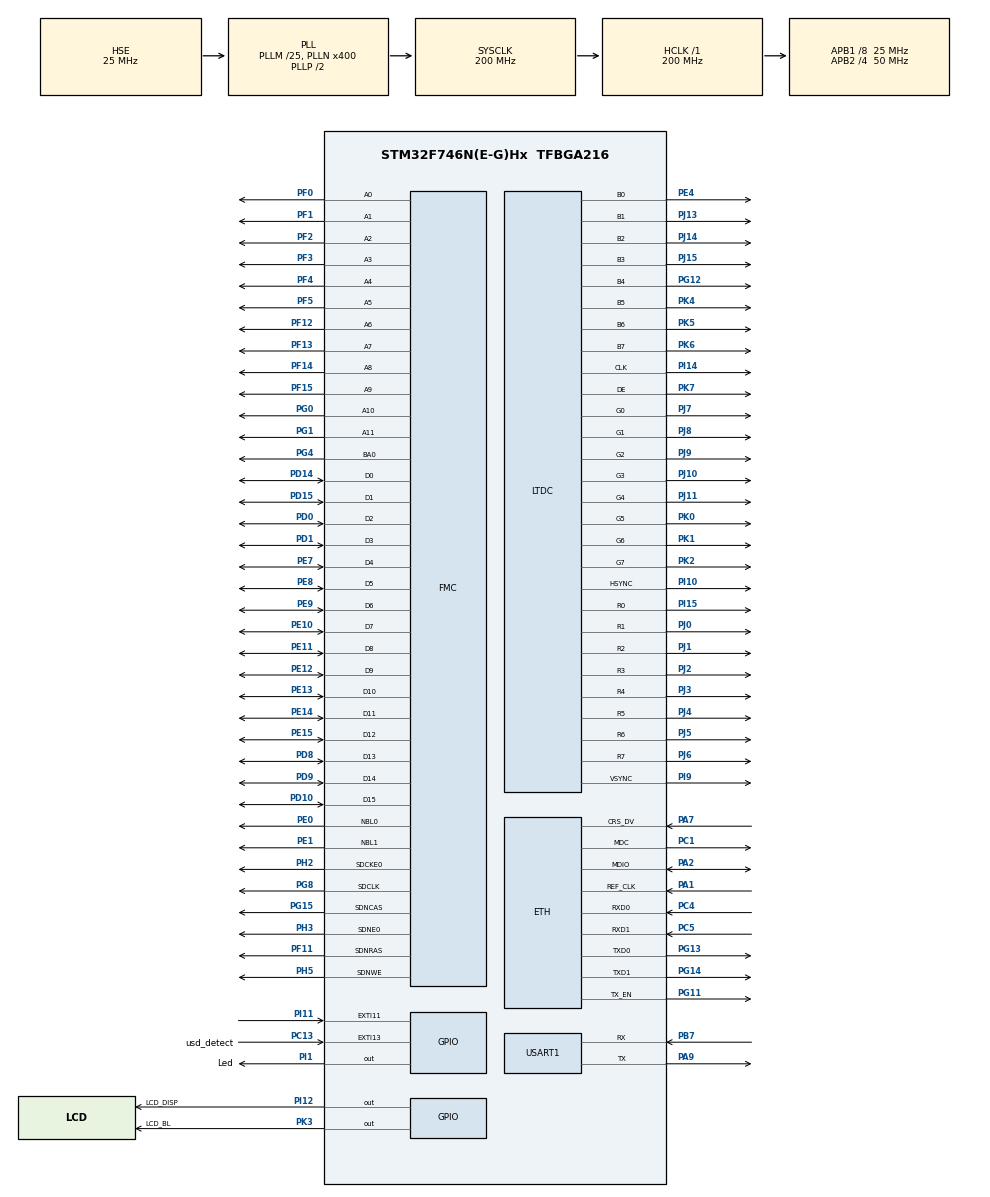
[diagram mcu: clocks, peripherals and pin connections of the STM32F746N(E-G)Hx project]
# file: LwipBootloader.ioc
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DMA2D.ColorMode=DMA2D_OUTPUT_ARGB1555
DMA2D.InputAlphaForeground=0
DMA2D.InputColorModeForeground=DMA2D_INPUT_A8
DMA2D.InputOffsetForeground=121
DMA2D.Mode=DMA2D_M2M_PFC
DMA2D.OutputOffset=473
ETH.MediaInterface=ETH_MEDIA_INTERFACE_RMII
ETH.PhyAddress=0
LTDC.ActiveH=272
LTDC.ActiveW=480
LTDC.HBP=43
LTDC.HFP=8
LTDC.HSync=1
LTDC.VBP=12
LTDC.VFP=4
LTDC.VSync=1
LWIP.GATEWAY_ADDRESS=192.168.002.001
LWIP.IP_ADDRESS=192.168.002.002
LWIP.LWIP_DHCP=0
LWIP.LWIP_UDP=1
LWIP.NETMASK_ADDRESS=255.255.255.000
LWIP.Version=v1.5.0_RC0_20160211_Cube
Mcu.Family=STM32F7
Mcu.Name=STM32F746N(E-G)Hx
Mcu.Package=TFBGA216
NVIC.EXTI15_10_IRQn=true\:0\:0\:false\:false\:true
NVIC.PriorityGroup=NVIC_PRIORITYGROUP_4
NVIC.TIM2_IRQn=true\:0\:0\:false\:false\:true
PA1.Mode=RMII
PA1.Signal=ETH_REF_CLK
PA2.Mode=RMII
PA2.Signal=ETH_MDIO
PA7.Mode=RMII
PA7.Signal=ETH_CRS_DV
PA9.Mode=Asynchronous
PA9.Signal=USART1_TX
PB7.Mode=Asynchronous
PB7.Signal=USART1_RX
PC1.Mode=RMII
PC1.Signal=ETH_MDC
PC13.GPIO_Label=usd_detect
PC13.GPIO_ModeDefaultEXTI=GPIO_MODE_IT_FALLING
PC13.Signal=GPXTI13
PC14/OSC32_IN.Mode=LSE-External-Oscillator
PC14/OSC32_IN.Signal=RCC_OSC32_IN
PC15/OSC32_OUT.Mode=LSE-External-Oscillator
PC15/OSC32_OUT.Signal=RCC_OSC32_OUT
PC4.Mode=RMII
PC4.Signal=ETH_RXD0
PC5.Mode=RMII
PC5.Signal=ETH_RXD1
PD0.Signal=FMC_D2_DA2
PD1.Signal=FMC_D3_DA3
PD10.Signal=FMC_D15_DA15
PD14.Signal=FMC_D0_DA0
PD15.Signal=FMC_D1_DA1
PD8.Signal=FMC_D13_DA13
PD9.Signal=FMC_D14_DA14
PE0.Signal=FMC_NBL0
PE1.Signal=FMC_NBL1
PE10.Signal=FMC_D7_DA7
PE11.Signal=FMC_D8_DA8
PE12.Signal=FMC_D9_DA9
PE13.Signal=FMC_D10_DA10
PE14.Signal=FMC_D11_DA11
PE15.Signal=FMC_D12_DA12
PE4.Mode=RGB888
PE4.Signal=LTDC_B0
PE7.Signal=FMC_D4_DA4
PE8.Signal=FMC_D5_DA5
PE9.Signal=FMC_D6_DA6
PF0.Signal=FMC_A0
PF1.Signal=FMC_A1
PF11.Signal=FMC_SDNRAS
PF12.Signal=FMC_A6
PF13.Signal=FMC_A7
PF14.Signal=FMC_A8
PF15.Signal=FMC_A9
PF2.Signal=FMC_A2
PF3.Signal=FMC_A3
PF4.Signal=FMC_A4
PF5.Signal=FMC_A5
PG0.Signal=FMC_A10
PG1.Signal=FMC_A11
PG11.Mode=RMII
PG11.Signal=ETH_TX_EN
PG12.Mode=RGB888
PG12.Signal=LTDC_B4
PG13.Mode=RMII
PG13.Signal=ETH_TXD0
PG14.Mode=RMII
PG14.Signal=ETH_TXD1
PG15.Signal=FMC_SDNCAS
PG4.Signal=FMC_A14_BA0
PG8.Signal=FMC_SDCLK
PH0/OSC_IN.Mode=HSE-External-Oscillator
PH0/OSC_IN.Signal=RCC_OSC_IN
PH1/OSC_OUT.Mode=HSE-External-Oscillator
PH1/OSC_OUT.Signal=RCC_OSC_OUT
PH2.Mode=SdramChipSelect1_1
PH2.Signal=FMC_SDCKE0
PH3.Mode=SdramChipSelect1_1
PH3.Signal=FMC_SDNE0
PH5.Signal=FMC_SDNWE
PH7.Signal=I2C3_SCL
PH8.Signal=I2C3_SDA
PI1.GPIO_Label=Led
PI1.Signal=GPIO_Output
PI10.Mode=RGB888
PI10.Signal=LTDC_HSYNC
PI11.Signal=GPXTI11
PI12.GPIO_Label=LCD_DISP
PI12.Signal=GPIO_Output
PI14.Mode=RGB888
PI14.Signal=LTDC_CLK
PI15.Mode=RGB888
PI15.Signal=LTDC_R0
PI9.Mode=RGB888
PI9.Signal=LTDC_VSYNC
PJ0.Mode=RGB888
PJ0.Signal=LTDC_R1
PJ1.Mode=RGB888
PJ1.Signal=LTDC_R2
PJ10.Mode=RGB888
PJ10.Signal=LTDC_G3
PJ11.Mode=RGB888
PJ11.Signal=LTDC_G4
PJ13.Mode=RGB888
PJ13.Signal=LTDC_B1
PJ14.Mode=RGB888
PJ14.Signal=LTDC_B2
PJ15.Mode=RGB888
PJ15.Signal=LTDC_B3
PJ2.Mode=RGB888
PJ2.Signal=LTDC_R3
PJ3.Mode=RGB888
PJ3.Signal=LTDC_R4
PJ4.Mode=RGB888
PJ4.Signal=LTDC_R5
PJ5.Mode=RGB888
PJ5.Signal=LTDC_R6
PJ6.Mode=RGB888
PJ6.Signal=LTDC_R7
PJ7.Mode=RGB888
PJ7.Signal=LTDC_G0
PJ8.Mode=RGB888
PJ8.Signal=LTDC_G1
PJ9.Mode=RGB888
PJ9.Signal=LTDC_G2
PK0.Mode=RGB888
PK0.Signal=LTDC_G5
PK1.Mode=RGB888
PK1.Signal=LTDC_G6
PK2.Mode=RGB888
PK2.Signal=LTDC_G7
PK3.GPIO_Label=LCD_BL
PK3.Signal=GPIO_Output
PK4.Mode=RGB888
PK4.Signal=LTDC_B5
PK5.Mode=RGB888
PK5.Signal=LTDC_B6
PK6.Mode=RGB888
PK6.Signal=LTDC_B7
PK7.Mode=RGB888
PK7.Signal=LTDC_DE
ProjectManager.HeapSize=0x200
ProjectManager.StackSize=0x400
ProjectManager.TargetToolchain=SW4STM32
RCC.AHBFreq_Value=200000000
RCC.APB1CLKDivider=RCC_HCLK_DIV8
RCC.APB1Freq_Value=25000000
RCC.APB1TimFreq_Value=50000000
RCC.APB2CLKDivider=RCC_HCLK_DIV4
RCC.APB2Freq_Value=50000000
RCC.APB2TimFreq_Value=100000000
RCC.CortexFreq_Value=200000000
RCC.HCLKFreq_Value=200000000
RCC.HSE_VALUE=25000000
RCC.HSI_VALUE=16000000
RCC.PLLM=25
RCC.PLLN=400
RCC.PLLQ=8
RCC.PLLSAIR=5
RCC.PLLSAIRDiv=RCC_PLLSAIDIVR_4
RCC.PLLSourceVirtual=RCC_PLLSOURCE_HSE
RCC.SDMMCClockSelection=RCC_SDMMC1CLKSOURCE_CLK48
RCC.SYSCLKFreq_VALUE=200000000
RCC.SYSCLKSource=RCC_SYSCLKSOURCE_PLLCLK
RCC.USBFreq_Value=50000000
RCC.VCOOutputFreq_Value=400000000
SH.FMC_A0.0=FMC_A0,12b-sda1
SH.FMC_A1.0=FMC_A1,12b-sda1
SH.FMC_A10.0=FMC_A10,12b-sda1
SH.FMC_A11.0=FMC_A11,12b-sda1
SH.FMC_A14_BA0.0=FMC_BA0,TwoSdramBanks1
SH.FMC_A2.0=FMC_A2,12b-sda1
SH.FMC_A3.0=FMC_A3,12b-sda1
SH.FMC_A4.0=FMC_A4,12b-sda1
SH.FMC_A5.0=FMC_A5,12b-sda1
SH.FMC_A6.0=FMC_A6,12b-sda1
SH.FMC_A7.0=FMC_A7,12b-sda1
SH.FMC_A8.0=FMC_A8,12b-sda1
SH.FMC_A9.0=FMC_A9,12b-sda1
SH.FMC_D0_DA0.0=FMC_D0,sd-16b-d1
SH.FMC_D10_DA10.0=FMC_D10,sd-16b-d1
SH.FMC_D11_DA11.0=FMC_D11,sd-16b-d1
SH.FMC_D12_DA12.0=FMC_D12,sd-16b-d1
SH.FMC_D13_DA13.0=FMC_D13,sd-16b-d1
SH.FMC_D14_DA14.0=FMC_D14,sd-16b-d1
SH.FMC_D15_DA15.0=FMC_D15,sd-16b-d1
SH.FMC_D1_DA1.0=FMC_D1,sd-16b-d1
SH.FMC_D2_DA2.0=FMC_D2,sd-16b-d1
SH.FMC_D3_DA3.0=FMC_D3,sd-16b-d1
SH.FMC_D4_DA4.0=FMC_D4,sd-16b-d1
SH.FMC_D5_DA5.0=FMC_D5,sd-16b-d1
SH.FMC_D6_DA6.0=FMC_D6,sd-16b-d1
SH.FMC_D7_DA7.0=FMC_D7,sd-16b-d1
SH.FMC_D8_DA8.0=FMC_D8,sd-16b-d1
SH.FMC_D9_DA9.0=FMC_D9,sd-16b-d1
SH.FMC_NBL0.0=FMC_NBL0,Sd2ByteEnable1
SH.FMC_NBL1.0=FMC_NBL1,Sd2ByteEnable1
SH.FMC_SDCLK.0=FMC_SDCLK,12b-sda1
SH.FMC_SDNCAS.0=FMC_SDNCAS,12b-sda1
SH.FMC_SDNRAS.0=FMC_SDNRAS,12b-sda1
SH.FMC_SDNWE.0=FMC_SDNWE,12b-sda1
TIM2.Period=500
TIM2.Prescaler=50000
USART1.WordLength=UART_WORDLENGTH_8B
VP_DMA2D_VS_DMA2D.Mode=DMA2D_Activate
VP_LWIP_VS_Enabled.Mode=Enabled
VP_TIM2_VS_ClockSourceINT.Mode=Internal
board=STM32F746G-DISCO

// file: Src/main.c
/**
  ******************************************************************************
  * File Name          : main.c
  * Description        : Main program body
  ******************************************************************************
  *
  * Copyright (c) 2016 STMicroelectronics International N.V.
  * All rights reserved.
  *
  * Redistribution and use in source and binary forms, with or without
  * modification, are permitted, provided that the following conditions are met:
  *
  * 1. Redistribution of source code must retain the above copyright notice,
  *    this list of conditions and the following disclaimer.
  * 2. Redistributions in binary form must reproduce the above copyright notice,
  *    this list of conditions and the following disclaimer in the documentation
  *    and/or other materials provided with the distribution.
  * 3. Neither the name of STMicroelectronics nor the names of other
  *    contributors to this software may be used to endorse or promote products
  *    derived from this software without specific written permission.
  * 4. This software, including modifications and/or derivative works of this
  *    software, must execute solely and exclusively on microcontroller or
  *    microprocessor devices manufactured by or for STMicroelectronics.
  * 5. Redistribution and use of this software other than as permitted under
  *    this license is void and will automatically terminate your rights under
  *    this license.
  *
  * THIS SOFTWARE IS PROVIDED BY STMICROELECTRONICS AND CONTRIBUTORS "AS IS"
  * AND ANY EXPRESS, IMPLIED OR STATUTORY WARRANTIES, INCLUDING, BUT NOT
  * LIMITED TO, THE IMPLIED WARRANTIES OF MERCHANTABILITY, FITNESS FOR A
  * PARTICULAR PURPOSE AND NON-INFRINGEMENT OF THIRD PARTY INTELLECTUAL PROPERTY
  * RIGHTS ARE DISCLAIMED TO THE FULLEST EXTENT PERMITTED BY LAW. IN NO EVENT
  * SHALL STMICROELECTRONICS OR CONTRIBUTORS BE LIABLE FOR ANY DIRECT, INDIRECT,
  * INCIDENTAL, SPECIAL, EXEMPLARY, OR CONSEQUENTIAL DAMAGES (INCLUDING, BUT NOT
  * LIMITED TO, PROCUREMENT OF SUBSTITUTE GOODS OR SERVICES; LOSS OF USE, DATA,
  * OR PROFITS; OR BUSINESS INTERRUPTION) HOWEVER CAUSED AND ON ANY THEORY OF
  * LIABILITY, WHETHER IN CONTRACT, STRICT LIABILITY, OR TORT (INCLUDING
  * NEGLIGENCE OR OTHERWISE) ARISING IN ANY WAY OUT OF THE USE OF THIS SOFTWARE,
  * EVEN IF ADVISED OF THE POSSIBILITY OF SUCH DAMAGE.
  *
  ******************************************************************************
  */
#include "main.h"
#include "stm32f7xx_hal.h"
#include "lwip.h"

/* USER CODE BEGIN Includes */

#include "tcp.h"
#include "udp.h"
#include "oli/oli_tcp.h"
#include "oli/oli_discover.h"
#include "oli/oli_text.h"
#include "oli/oli_bootloader.h"

#include "sdram/stm32746g_discovery_sdram.h"

/* Begin defines */

#define mainLCD_FB_START_ADDRESS       ((uint32_t)0xC0000000)

/* End defines */

/* USER CODE END Includes */

DMA2D_HandleTypeDef hdma2d;
LTDC_HandleTypeDef hltdc;
TIM_HandleTypeDef htim2;
UART_HandleTypeDef huart1;
SDRAM_HandleTypeDef hsdram1;

/* USER CODE BEGIN PV */
/* Private variables ---------------------------------------------------------*/

/**
 * Bij deze variabele word er een sectie aangemaakt in het geheugen.
 * Het doel is om deze variabele in het begin van de ram te plaatsen(0x20000000).
 * Dit moet omdat deze gebruikt zal worden een een dynamische vectortabel in te laden voor de user applicatie.
 * Deze sectie wordt gedefinierd in het linker script
 */
__attribute__((section(".user_vector"))) uint32_t userVectorTable[80];

uint8_t ucUserAppIsRunning = 0;
uint8_t * pucUserAppName = otcpAPPLICATION_NAME_ADDRESS;

/* USER CODE END PV */

void SystemClock_Config(void);
void Error_Handler(void);
static void MX_GPIO_Init(void);
static void MX_LTDC_Init(void);
static void MX_DMA2D_Init(void);
static void MX_USART1_UART_Init(void);
static void MX_TIM2_Init(void);
static void MX_FMC_Init(void);

/* USER CODE BEGIN PFP */
/* Private function prototypes -----------------------------------------------*/

err_t xMainClientConnected( void * pvArg, struct tcp_pcb * pxNewpcb, err_t xErr );

/*-----------------------------------------------------------*/

/* USER CODE END PFP */

int main(void)
{

  /* USER CODE BEGIN 1 */

	MX_GPIO_Init();
	MX_TIM2_Init();
	// We kijken of de knop ingedrukt is
	if( !HAL_GPIO_ReadPin( GPIOI, GPIO_PIN_11 ) && *pucUserAppName != 15 )
	{
		// Als de knop niet ingedrukt is springen we naar het programma in flash
		vObootloaderJumpToApplication( otcpAPPLICATION_ADDRESS );
	}

	if( *pucUserAppName == 15 )
	{
		// We zijn herstart zoals gevraagd over udp, nu terug naar normale werking
		// We moeten dus terug 14 voor de user-app naam schrijven
		HAL_FLASH_Unlock();
		HAL_FLASH_Program( FLASH_TYPEPROGRAM_BYTE, otcpAPPLICATION_NAME_ADDRESS, 14 );
		HAL_FLASH_Lock();
	}

  /* USER CODE END 1 */

  /* MCU Configuration----------------------------------------------------------*/

  /* Reset of all peripherals, Initializes the Flash interface and the Systick. */
  HAL_Init();

  /* Configure the system clock */
  SystemClock_Config();

  /* Initialize all configured peripherals */
  MX_GPIO_Init();
  MX_LTDC_Init();
  MX_DMA2D_Init();
  MX_USART1_UART_Init();
  MX_LWIP_Init();
  MX_TIM2_Init();
  MX_FMC_Init();

  /* USER CODE BEGIN 2 */

  struct ip4_addr xServerIp;
  struct tcp_pcb * pxTcpConnectie;

  IP4_ADDR( &xServerIp, 192, 168, 2, 2 );

  // We maken een nieuwe tcp server en laten deze luisteren op poort 5555
  pxTcpConnectie = tcp_new();
  tcp_bind( pxTcpConnectie, &xServerIp, otcpBOOTLOADER_SERVER_PORT );
  pxTcpConnectie = tcp_listen_with_backlog( pxTcpConnectie, 1 );
  if( pxTcpConnectie != NULL )
  {
	  tcp_accept( pxTcpConnectie, xMainClientConnected );
  }

  // We initialiseren udp zodat we op het netwerk gevonden kunnen worden via een broadcast
  vOdiscoverInitUdpDiscover();

  // We tonen een welcomeMessage op het lcd
  BSP_SDRAM_Init();
  vOtextInitLcd( &hltdc, &hdma2d, mainLCD_FB_START_ADDRESS );
  vOtextWriteString( 184, 50, otcpWELCOME );

  /* USER CODE END 2 */

  /* Infinite loop */
  while ( 1 )
  {

  /* USER CODE BEGIN 3 */

	  MX_LWIP_Process();

  }
  /* USER CODE END 3 */

}

/** System Clock Configuration
*/
void SystemClock_Config(void)
{

  RCC_OscInitTypeDef RCC_OscInitStruct;
  RCC_ClkInitTypeDef RCC_ClkInitStruct;
  RCC_PeriphCLKInitTypeDef PeriphClkInitStruct;

    /**Configure the main internal regulator output voltage
    */
  __HAL_RCC_PWR_CLK_ENABLE();

  __HAL_PWR_VOLTAGESCALING_CONFIG(PWR_REGULATOR_VOLTAGE_SCALE1);

    /**Initializes the CPU, AHB and APB busses clocks
    */
  RCC_OscInitStruct.OscillatorType = RCC_OSCILLATORTYPE_HSE;
  RCC_OscInitStruct.HSEState = RCC_HSE_ON;
  RCC_OscInitStruct.PLL.PLLState = RCC_PLL_ON;
  RCC_OscInitStruct.PLL.PLLSource = RCC_PLLSOURCE_HSE;
  RCC_OscInitStruct.PLL.PLLM = 25;
  RCC_OscInitStruct.PLL.PLLN = 400;
  RCC_OscInitStruct.PLL.PLLP = RCC_PLLP_DIV2;
  RCC_OscInitStruct.PLL.PLLQ = 8;
  if (HAL_RCC_OscConfig(&RCC_OscInitStruct) != HAL_OK)
  {
    Error_Handler();
  }

    /**Activate the Over-Drive mode
    */
  if (HAL_PWREx_EnableOverDrive() != HAL_OK)
  {
    Error_Handler();
  }

    /**Initializes the CPU, AHB and APB busses clocks
    */
  RCC_ClkInitStruct.ClockType = RCC_CLOCKTYPE_HCLK|RCC_CLOCKTYPE_SYSCLK
                              |RCC_CLOCKTYPE_PCLK1|RCC_CLOCKTYPE_PCLK2;
  RCC_ClkInitStruct.SYSCLKSource = RCC_SYSCLKSOURCE_PLLCLK;
  RCC_ClkInitStruct.AHBCLKDivider = RCC_SYSCLK_DIV1;
  RCC_ClkInitStruct.APB1CLKDivider = RCC_HCLK_DIV8;
  RCC_ClkInitStruct.APB2CLKDivider = RCC_HCLK_DIV4;

  if (HAL_RCC_ClockConfig(&RCC_ClkInitStruct, FLASH_LATENCY_6) != HAL_OK)
  {
    Error_Handler();
  }

  PeriphClkInitStruct.PeriphClockSelection = RCC_PERIPHCLK_LTDC|RCC_PERIPHCLK_USART1;
  PeriphClkInitStruct.PLLSAI.PLLSAIN = 192;
  PeriphClkInitStruct.PLLSAI.PLLSAIR = 5;
  PeriphClkInitStruct.PLLSAI.PLLSAIQ = 2;
  PeriphClkInitStruct.PLLSAI.PLLSAIP = RCC_PLLSAIP_DIV2;
  PeriphClkInitStruct.PLLSAIDivQ = 1;
  PeriphClkInitStruct.PLLSAIDivR = RCC_PLLSAIDIVR_4;
  PeriphClkInitStruct.Usart1ClockSelection = RCC_USART1CLKSOURCE_PCLK2;
  if (HAL_RCCEx_PeriphCLKConfig(&PeriphClkInitStruct) != HAL_OK)
  {
    Error_Handler();
  }

    /**Configure the Systick interrupt time
    */
  HAL_SYSTICK_Config(HAL_RCC_GetHCLKFreq()/1000);

    /**Configure the Systick
    */
  HAL_SYSTICK_CLKSourceConfig(SYSTICK_CLKSOURCE_HCLK);

  /* SysTick_IRQn interrupt configuration */
  HAL_NVIC_SetPriority(SysTick_IRQn, 0, 0);
}

/* DMA2D init function */
static void MX_DMA2D_Init(void)
{

  hdma2d.Instance = DMA2D;
  hdma2d.Init.Mode = DMA2D_M2M_PFC;
  hdma2d.Init.ColorMode = DMA2D_OUTPUT_ARGB1555;
  hdma2d.Init.OutputOffset = 473;
  hdma2d.LayerCfg[1].InputOffset = 121;
  hdma2d.LayerCfg[1].InputColorMode = DMA2D_INPUT_A8;
  hdma2d.LayerCfg[1].AlphaMode = DMA2D_NO_MODIF_ALPHA;
  hdma2d.LayerCfg[1].InputAlpha = 0;
  if (HAL_DMA2D_Init(&hdma2d) != HAL_OK)
  {
    Error_Handler();
  }

  if (HAL_DMA2D_ConfigLayer(&hdma2d, 1) != HAL_OK)
  {
    Error_Handler();
  }

}

/* LTDC init function */
static void MX_LTDC_Init(void)
{

  LTDC_LayerCfgTypeDef pLayerCfg;
  LTDC_LayerCfgTypeDef pLayerCfg1;

  hltdc.Instance = LTDC;
  hltdc.Init.HSPolarity = LTDC_HSPOLARITY_AL;
  hltdc.Init.VSPolarity = LTDC_VSPOLARITY_AL;
  hltdc.Init.DEPolarity = LTDC_DEPOLARITY_AL;
  hltdc.Init.PCPolarity = LTDC_PCPOLARITY_IPC;
  hltdc.Init.HorizontalSync = 0;
  hltdc.Init.VerticalSync = 0;
  hltdc.Init.AccumulatedHBP = 43;
  hltdc.Init.AccumulatedVBP = 12;
  hltdc.Init.AccumulatedActiveW = 523;
  hltdc.Init.AccumulatedActiveH = 284;
  hltdc.Init.TotalWidth = 531;
  hltdc.Init.TotalHeigh = 288;
  hltdc.Init.Backcolor.Blue = 0;
  hltdc.Init.Backcolor.Green = 0;
  hltdc.Init.Backcolor.Red = 0;
  if (HAL_LTDC_Init(&hltdc) != HAL_OK)
  {
    Error_Handler();
  }

  pLayerCfg.WindowX0 = 0;
  pLayerCfg.WindowX1 = 0;
  pLayerCfg.WindowY0 = 0;
  pLayerCfg.WindowY1 = 0;
  pLayerCfg.PixelFormat = LTDC_PIXEL_FORMAT_ARGB8888;
  pLayerCfg.Alpha = 0;
  pLayerCfg.Alpha0 = 0;
  pLayerCfg.BlendingFactor1 = LTDC_BLENDING_FACTOR1_CA;
  pLayerCfg.BlendingFactor2 = LTDC_BLENDING_FACTOR2_CA;
  pLayerCfg.FBStartAdress = 0;
  pLayerCfg.ImageWidth = 0;
  pLayerCfg.ImageHeight = 0;
  pLayerCfg.Backcolor.Blue = 0;
  pLayerCfg.Backcolor.Green = 0;
  pLayerCfg.Backcolor.Red = 0;
  if (HAL_LTDC_ConfigLayer(&hltdc, &pLayerCfg, 0) != HAL_OK)
  {
    Error_Handler();
  }

  pLayerCfg1.WindowX0 = 0;
  pLayerCfg1.WindowX1 = 0;
  pLayerCfg1.WindowY0 = 0;
  pLayerCfg1.WindowY1 = 0;
  pLayerCfg1.PixelFormat = LTDC_PIXEL_FORMAT_ARGB8888;
  pLayerCfg1.Alpha = 0;
  pLayerCfg1.Alpha0 = 0;
  pLayerCfg1.BlendingFactor1 = LTDC_BLENDING_FACTOR1_CA;
  pLayerCfg1.BlendingFactor2 = LTDC_BLENDING_FACTOR2_CA;
  pLayerCfg1.FBStartAdress = 0;
  pLayerCfg1.ImageWidth = 0;
  pLayerCfg1.ImageHeight = 0;
  pLayerCfg1.Backcolor.Blue = 0;
  pLayerCfg1.Backcolor.Green = 0;
  pLayerCfg1.Backcolor.Red = 0;
  if (HAL_LTDC_ConfigLayer(&hltdc, &pLayerCfg1, 1) != HAL_OK)
  {
    Error_Handler();
  }

}

/* TIM2 init function */
static void MX_TIM2_Init(void)
{

  TIM_ClockConfigTypeDef sClockSourceConfig;
  TIM_MasterConfigTypeDef sMasterConfig;

  htim2.Instance = TIM2;
  htim2.Init.Prescaler = 50000;
  htim2.Init.CounterMode = TIM_COUNTERMODE_UP;
  htim2.Init.Period = 500;
  htim2.Init.ClockDivision = TIM_CLOCKDIVISION_DIV1;
  if (HAL_TIM_Base_Init(&htim2) != HAL_OK)
  {
    Error_Handler();
  }

  sClockSourceConfig.ClockSource = TIM_CLOCKSOURCE_INTERNAL;
  if (HAL_TIM_ConfigClockSource(&htim2, &sClockSourceConfig) != HAL_OK)
  {
    Error_Handler();
  }

  sMasterConfig.MasterOutputTrigger = TIM_TRGO_RESET;
  sMasterConfig.MasterSlaveMode = TIM_MASTERSLAVEMODE_DISABLE;
  if (HAL_TIMEx_MasterConfigSynchronization(&htim2, &sMasterConfig) != HAL_OK)
  {
    Error_Handler();
  }

}

/* USART1 init function */
static void MX_USART1_UART_Init(void)
{

  huart1.Instance = USART1;
  huart1.Init.BaudRate = 115200;
  huart1.Init.WordLength = UART_WORDLENGTH_8B;
  huart1.Init.StopBits = UART_STOPBITS_1;
  huart1.Init.Parity = UART_PARITY_NONE;
  huart1.Init.Mode = UART_MODE_TX_RX;
  huart1.Init.HwFlowCtl = UART_HWCONTROL_NONE;
  huart1.Init.OverSampling = UART_OVERSAMPLING_16;
  huart1.Init.OneBitSampling = UART_ONE_BIT_SAMPLE_DISABLE;
  huart1.AdvancedInit.AdvFeatureInit = UART_ADVFEATURE_NO_INIT;
  if (HAL_UART_Init(&huart1) != HAL_OK)
  {
    Error_Handler();
  }

}
/* FMC initialization function */
static void MX_FMC_Init(void)
{
  FMC_SDRAM_TimingTypeDef SdramTiming;

  /** Perform the SDRAM1 memory initialization sequence
  */
  hsdram1.Instance = FMC_SDRAM_DEVICE;
  /* hsdram1.Init */
  hsdram1.Init.SDBank = FMC_SDRAM_BANK1;
  hsdram1.Init.ColumnBitsNumber = FMC_SDRAM_COLUMN_BITS_NUM_8;
  hsdram1.Init.RowBitsNumber = FMC_SDRAM_ROW_BITS_NUM_12;
  hsdram1.Init.MemoryDataWidth = FMC_SDRAM_MEM_BUS_WIDTH_16;
  hsdram1.Init.InternalBankNumber = FMC_SDRAM_INTERN_BANKS_NUM_2;
  hsdram1.Init.CASLatency = FMC_SDRAM_CAS_LATENCY_1;
  hsdram1.Init.WriteProtection = FMC_SDRAM_WRITE_PROTECTION_DISABLE;
  hsdram1.Init.SDClockPeriod = FMC_SDRAM_CLOCK_DISABLE;
  hsdram1.Init.ReadBurst = FMC_SDRAM_RBURST_DISABLE;
  hsdram1.Init.ReadPipeDelay = FMC_SDRAM_RPIPE_DELAY_0;
  /* SdramTiming */
  SdramTiming.LoadToActiveDelay = 16;
  SdramTiming.ExitSelfRefreshDelay = 16;
  SdramTiming.SelfRefreshTime = 16;
  SdramTiming.RowCycleDelay = 16;
  SdramTiming.WriteRecoveryTime = 16;
  SdramTiming.RPDelay = 16;
  SdramTiming.RCDDelay = 16;

  if (HAL_SDRAM_Init(&hsdram1, &SdramTiming) != HAL_OK)
  {
    Error_Handler();
  }

}

/** Configure pins as
        * Analog
        * Input
        * Output
        * EVENT_OUT
        * EXTI
     PH7   ------> I2C3_SCL
     PH8   ------> I2C3_SDA
*/
static void MX_GPIO_Init(void)
{

  GPIO_InitTypeDef GPIO_InitStruct;

  /* GPIO Ports Clock Enable */
  __HAL_RCC_GPIOE_CLK_ENABLE();
  __HAL_RCC_GPIOG_CLK_ENABLE();
  __HAL_RCC_GPIOB_CLK_ENABLE();
  __HAL_RCC_GPIOJ_CLK_ENABLE();
  __HAL_RCC_GPIOD_CLK_ENABLE();
  __HAL_RCC_GPIOK_CLK_ENABLE();
  __HAL_RCC_GPIOC_CLK_ENABLE();
  __HAL_RCC_GPIOF_CLK_ENABLE();
  __HAL_RCC_GPIOI_CLK_ENABLE();
  __HAL_RCC_GPIOA_CLK_ENABLE();
  __HAL_RCC_GPIOH_CLK_ENABLE();

  /*Configure GPIO pin : usd_detect_Pin */
  GPIO_InitStruct.Pin = usd_detect_Pin;
  GPIO_InitStruct.Mode = GPIO_MODE_IT_FALLING;
  GPIO_InitStruct.Pull = GPIO_NOPULL;
  HAL_GPIO_Init(usd_detect_GPIO_Port, &GPIO_InitStruct);

  /*Configure GPIO pin : LCD_BL_Pin */
  GPIO_InitStruct.Pin = LCD_BL_Pin;
  GPIO_InitStruct.Mode = GPIO_MODE_OUTPUT_PP;
  GPIO_InitStruct.Pull = GPIO_NOPULL;
  GPIO_InitStruct.Speed = GPIO_SPEED_FREQ_LOW;
  HAL_GPIO_Init(LCD_BL_GPIO_Port, &GPIO_InitStruct);

  /*Configure GPIO pins : Led_Pin LCD_DISP_Pin */
  GPIO_InitStruct.Pin = Led_Pin|LCD_DISP_Pin;
  GPIO_InitStruct.Mode = GPIO_MODE_OUTPUT_PP;
  GPIO_InitStruct.Pull = GPIO_NOPULL;
  GPIO_InitStruct.Speed = GPIO_SPEED_FREQ_LOW;
  HAL_GPIO_Init(GPIOI, &GPIO_InitStruct);

  /*Configure GPIO pin : PI11 */
  GPIO_InitStruct.Pin = GPIO_PIN_11;
  GPIO_InitStruct.Mode = GPIO_MODE_IT_RISING;
  GPIO_InitStruct.Pull = GPIO_NOPULL;
  HAL_GPIO_Init(GPIOI, &GPIO_InitStruct);

  /*Configure GPIO pins : PH7 PH8 */
  GPIO_InitStruct.Pin = GPIO_PIN_7|GPIO_PIN_8;
  GPIO_InitStruct.Mode = GPIO_MODE_AF_OD;
  GPIO_InitStruct.Pull = GPIO_PULLUP;
  GPIO_InitStruct.Speed = GPIO_SPEED_FREQ_VERY_HIGH;
  GPIO_InitStruct.Alternate = GPIO_AF4_I2C3;
  HAL_GPIO_Init(GPIOH, &GPIO_InitStruct);

  /*Configure GPIO pin Output Level */
  HAL_GPIO_WritePin(LCD_BL_GPIO_Port, LCD_BL_Pin, GPIO_PIN_RESET);

  /*Configure GPIO pin Output Level */
  HAL_GPIO_WritePin(GPIOI, Led_Pin|LCD_DISP_Pin, GPIO_PIN_RESET);

  /* EXTI interrupt init*/
  HAL_NVIC_SetPriority(EXTI15_10_IRQn, 0, 0);
  HAL_NVIC_EnableIRQ(EXTI15_10_IRQn);

}

/* USER CODE BEGIN 4 */

/**
 * @brief      Het serverprogramma is succesvol geconnecteerd, vanaf nu luisteren we naar commando's
 *
 * @param      pvArg     Extra argumenten van lwip
 * @param      pxNewpcb  De tcp-connectie
 * @param[in]  xErr      De errors van lwip
 *
 * @return     return aan lwip of er een error was
 */
err_t xMainClientConnected( void * pvArg, struct tcp_pcb * pxNewpcb, err_t xErr )
{
	tcp_recv( pxNewpcb, xOtcpReadMenuCommando );

	return ERR_OK;
}
/*-----------------------------------------------------------*/

/* USER CODE END 4 */

void Error_Handler(void)
{
  while(1)
  {
  }
}

/************************ (C) COPYRIGHT STMicroelectronics *****END OF FILE****/
